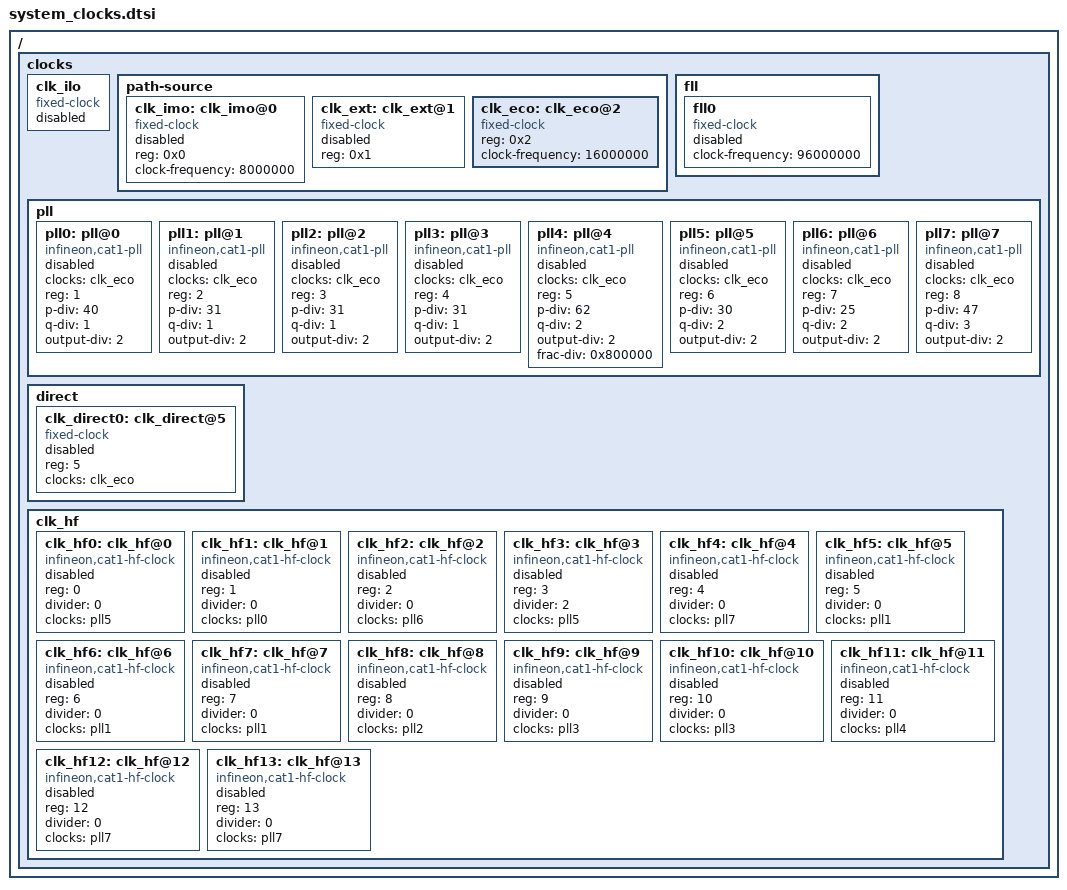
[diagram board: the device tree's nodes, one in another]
/*
 * Copyright (c) 2025 Linumiz GmbH 
 *
 * SPDX-License-Identifier: Apache-2.0
 */


#define DIV_8_BIT	00
#define DIV_16_BIT	01
#define DIV_16_5_BIT	02
#define DIV_24_5_BIT	03

#include <dt-bindings/clock/ifx_clock_source_def.h>

/ {
	clocks {
		/* ilo */
		clk_ilo: clk_ilo {
			#clock-cells = <0>;
			compatible = "fixed-clock";
			status = "disabled";
		};

		path-source {
			#address-cells = <1>;
			#size-cells = <0>;

			/* imo */
			clk_imo: clk_imo@0 {
				#clock-cells = <0>;
				reg = <0x0>;
				compatible = "fixed-clock";
				clock-frequency = <8000000>;
				status = "disabled";
			};

			/* ext_clk */
			clk_ext: clk_ext@1 {
				#clock-cells = <0>;
				compatible = "fixed-clock";
				reg = <0x1>;
				status = "disabled";
			};

			/* eco */
			clk_eco: clk_eco@2 {
				#clock-cells = <0>;
				compatible = "fixed-clock";
				reg = <0x2>;
				clock-frequency = <16000000>;
				status = "okay";
			};
		};

		fll {
			#address-cells = <1>;
			#size-cells = <0>;

			/* fll */
			fll0: fll0 {
				#clock-cells = <0>;
				compatible = "fixed-clock";
				clock-frequency = <96000000>;
				status = "disabled";
			};
		};

		pll {
			#address-cells = <1>;
			#size-cells = <0>;

			pll0: pll@0 {
				#clock-cells = <0>;
				compatible = "infineon,cat1-pll";
				clocks = <&clk_eco>;
				reg = <1>;
				p-div = <40>;
				q-div = <1>;
				output-div = <2>;
				status = "disabled";
			};

			pll1: pll@1 {
				#clock-cells = <0>;
				compatible = "infineon,cat1-pll";
				clocks = <&clk_eco>;
				reg = <2>;
				p-div = <31>;
				q-div = <1>;
				output-div = <2>;
				status = "disabled";
			};

			pll2: pll@2 {
				#clock-cells = <0>;
				compatible = "infineon,cat1-pll";
				clocks = <&clk_eco>;
				reg = <3>;
				p-div = <31>;
				q-div = <1>;
				output-div = <2>;
				status = "disabled";
			};

			pll3: pll@3 {
				#clock-cells = <0>;
				compatible = "infineon,cat1-pll";
				clocks = <&clk_eco>;
				reg = <4>;
				p-div = <31>;
				q-div = <1>;
				output-div = <2>;
				status = "disabled";
			};

			pll4: pll@4 {
				#clock-cells = <0>;
				compatible = "infineon,cat1-pll";
				clocks = <&clk_eco>;
				reg = <5>;
				p-div = <62>;
				q-div = <2>;
				output-div = <2>;
				frac-div = <0x800000>;
				status = "disabled";
			};

			pll5: pll@5 {
				#clock-cells = <0>;
				compatible = "infineon,cat1-pll";
				clocks = <&clk_eco>;
				reg = <6>;
				p-div = <30>;
				q-div = <2>;
				output-div = <2>;
				status = "disabled";
			};

			pll6: pll@6 {
				#clock-cells = <0>;
				compatible = "infineon,cat1-pll";
				clocks = <&clk_eco>;
				reg = <7>;
				p-div = <25>;
				q-div = <2>;
				output-div = <2>;
				status = "disabled";
			};

			pll7: pll@7 {
				#clock-cells = <0>;
				compatible = "infineon,cat1-pll";
				clocks = <&clk_eco>;
				reg = <8>;
				p-div = <47>;
				q-div = <3>;
				output-div = <2>;
				status = "disabled";
			};
		};

		direct {
			#address-cells = <1>;
			#size-cells = <0>;
			clk_direct0: clk_direct@5 {
				#clock-cells = <0>;
				compatible = "fixed-clock";
				reg = <5>;
				clocks = <&clk_eco>;
				status = "disabled";
			};
		};

		clk_hf {
			#address-cells = <1>;
			#size-cells = <0>;

			/* clk_hf0 */
			clk_hf0: clk_hf@0 {
				#clock-cells = <0>;
				compatible = "infineon,cat1-hf-clock";
				reg = <0>;
				divider = <0>;
				clocks = <&pll5>;
				status = "disabled";
			};

			/* clk_hf1 */
			clk_hf1: clk_hf@1 {
				#clock-cells = <0>;
				compatible = "infineon,cat1-hf-clock";
				reg = <1>;
				divider = <0>;
				clocks = <&pll0>;
				status = "disabled";
			};

			/* clk_hf2 */
			clk_hf2: clk_hf@2 {
				#clock-cells = <0>;
				compatible = "infineon,cat1-hf-clock";
				reg = <2>;
				divider = <0>;
				clocks = <&pll6>;
				status = "disabled";
			};

			/* clk_hf3 */
			clk_hf3: clk_hf@3 {
				#clock-cells = <0>;
				compatible = "infineon,cat1-hf-clock";
				reg = <3>;
				divider = <2>;
				clocks = <&pll5>;
				status = "disabled";
			};

			/* clk_hf4 */
			clk_hf4: clk_hf@4 {
				#clock-cells = <0>;
				compatible = "infineon,cat1-hf-clock";
				reg = <4>;
				divider = <0>;
				clocks = <&pll7>;
				status = "disabled";
			};

			/* clk_hf5 */
			clk_hf5: clk_hf@5 {
				#clock-cells = <0>;
				compatible = "infineon,cat1-hf-clock";
				reg = <5>;
				divider = <0>;
				clocks = <&pll1>;
				status = "disabled";
			};

			/* clk_hf6 */
			clk_hf6: clk_hf@6 {
				#clock-cells = <0>;
				compatible = "infineon,cat1-hf-clock";
				reg = <6>;
				divider = <0>;
				clocks = <&pll1>;
				status = "disabled";
			};

			/* clk_hf7 */
			clk_hf7: clk_hf@7 {
				#clock-cells = <0>;
				compatible = "infineon,cat1-hf-clock";
				reg = <7>;
				divider = <0>;
				clocks = <&pll1>;
				status = "disabled";
			};

			/* clk_hf8 */
			clk_hf8: clk_hf@8 {
				#clock-cells = <0>;
				compatible = "infineon,cat1-hf-clock";
				reg = <8>;
				divider = <0>;
				clocks = <&pll2>;
				status = "disabled";
			};

			/* clk_hf9 */
			clk_hf9: clk_hf@9 {
				#clock-cells = <0>;
				compatible = "infineon,cat1-hf-clock";
				reg = <9>;
				divider = <0>;
				clocks = <&pll3>;
				status = "disabled";
			};

			/* clk_hf10 */
			clk_hf10: clk_hf@10 {
				#clock-cells = <0>;
				compatible = "infineon,cat1-hf-clock";
				reg = <10>;
				divider = <0>;
				clocks = <&pll3>;
				status = "disabled";
			};

			/* clk_hf11 */
			clk_hf11: clk_hf@11 {
				#clock-cells = <0>;
				compatible = "infineon,cat1-hf-clock";
				reg = <11>;
				divider = <0>;
				clocks = <&pll4>;
				status = "disabled";
			};

			/* clk_hf12 */
			clk_hf12: clk_hf@12 {
				#clock-cells = <0>;
				compatible = "infineon,cat1-hf-clock";
				reg = <12>;
				divider = <0>;
				clocks = <&pll7>;
				status = "disabled";
			};

			/* clk_hf13 */
			clk_hf13: clk_hf@13 {
				#clock-cells = <0>;
				compatible = "infineon,cat1-hf-clock";
				reg = <13>;
				divider = <0>;
				clocks = <&pll7>;
				status = "disabled";
			};
		};
	};
};
